# RP2040 register map
Vendor: Raspberry Pi; Series: RP; File version: 0.1
CPU: CM0PLUS r0p1, little endian, MPU, no FPU, VTOR, 2 interrupt priority bits, 32 interrupts
Registers are 32-bit, read-write, reset 0x0 unless marked. A register's access mark holds for its fields unless they carry their own. Offsets are from the block's base; [hi:lo] are bit positions; {n}, {i} and the like mark numbered series; 'fields as' and 'values as' point back to an identical list.

## CLOCKS
Base 0x40008000
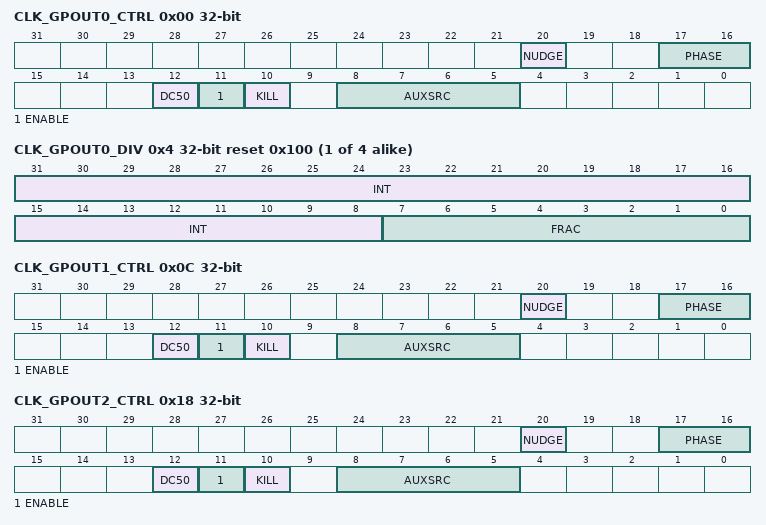
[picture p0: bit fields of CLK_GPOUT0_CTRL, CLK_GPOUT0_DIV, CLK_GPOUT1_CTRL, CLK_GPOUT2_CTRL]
0x00 CLK_GPOUT0_CTRL — Clock control, can be changed on-the-fly (except for auxsrc)
  [20] NUDGE — An edge on this signal shifts the phase of the output by 1 cycle of the input clock This can be done at any time
  [17:16] PHASE — This delays the enable signal by up to 3 cycles of the input clock This must be set before the clock is enabled to have any effect
  [12] DC50 — Enables duty cycle correction for odd divisors
  [11] ENABLE — Starts and stops the clock generator cleanly
  [10] KILL — Asynchronously kills the clock generator
  [8:5] AUXSRC — Selects the auxiliary clock source, will glitch when switching
    0=clksrc_pll_sys; 1=clksrc_gpin0; 2=clksrc_gpin1; 3=clksrc_pll_usb; 4=rosc_clksrc; 5=xosc_clksrc; 6=clk_sys; 7=clk_usb; 8=clk_adc; 9=clk_rtc; 10=clk_ref
{0x4+0xC*i} CLK_GPOUT{i}_DIV reset 0x100 (i=0..3) — Clock divisor, can be changed on-the-fly
  [31:8] INT — Integer component of the divisor, 0 -> divide by 2^16
  [7:0] FRAC — Fractional component of the divisor
{0x8+0xC*i} CLK_GPOUT{i}_SELECTED reset 0x1 (i=0..3) — Indicates which SRC is currently selected by the glitchless mux (one-hot).
  [31:0] CLK_GPOUT{i}_SELECTED ro — This slice does not have a glitchless mux (only the AUX_SRC field is present, not SRC) so this register is hardwired to 0x1.
0x0C CLK_GPOUT1_CTRL — Clock control, can be changed on-the-fly (except for auxsrc)
  fields as CLK_GPOUT0_CTRL
0x18 CLK_GPOUT2_CTRL — Clock control, can be changed on-the-fly (except for auxsrc)
  [20] NUDGE — An edge on this signal shifts the phase of the output by 1 cycle of the input clock This can be done at any time
  [17:16] PHASE — This delays the enable signal by up to 3 cycles of the input clock This must be set before the clock is enabled to have any effect
  [12] DC50 — Enables duty cycle correction for odd divisors
  [11] ENABLE — Starts and stops the clock generator cleanly
  [10] KILL — Asynchronously kills the clock generator
  [8:5] AUXSRC — Selects the auxiliary clock source, will glitch when switching
    0=clksrc_pll_sys; 1=clksrc_gpin0; 2=clksrc_gpin1; 3=clksrc_pll_usb; 4=rosc_clksrc_ph; 5=xosc_clksrc; 6=clk_sys; 7=clk_usb; 8=clk_adc; 9=clk_rtc; 10=clk_ref
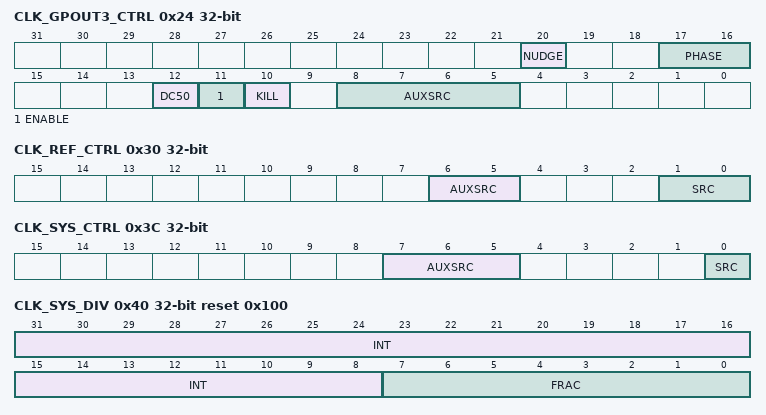
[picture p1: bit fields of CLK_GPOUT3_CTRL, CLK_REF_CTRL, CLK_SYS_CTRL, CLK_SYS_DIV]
0x24 CLK_GPOUT3_CTRL — Clock control, can be changed on-the-fly (except for auxsrc)
  fields as CLK_GPOUT2_CTRL
0x30 CLK_REF_CTRL — Clock control, can be changed on-the-fly (except for auxsrc)
  [6:5] AUXSRC — Selects the auxiliary clock source, will glitch when switching
    0=clksrc_pll_usb; 1=clksrc_gpin0; 2=clksrc_gpin1
  [1:0] SRC — Selects the clock source glitchlessly, can be changed on-the-fly
    0=rosc_clksrc_ph; 1=clksrc_clk_ref_aux; 2=xosc_clksrc
0x34 CLK_REF_DIV reset 0x100 — Clock divisor, can be changed on-the-fly
  [9:8] INT — Integer component of the divisor, 0 -> divide by 2^16
0x38 CLK_REF_SELECTED reset 0x1 — Indicates which SRC is currently selected by the glitchless mux (one-hot).
  [31:0] CLK_REF_SELECTED ro — The glitchless multiplexer does not switch instantaneously (to avoid glitches), so software should poll this register to wait for the switch to complete. This register contains one decoded bit for each of the clock sources enumerated in the CTRL SRC field. At most one of these bits will be set at any time, indicating that clock is currently present at the output of the glitchless mux. Whilst switching is in progress, this register may briefly show all-0s.
0x3C CLK_SYS_CTRL — Clock control, can be changed on-the-fly (except for auxsrc)
  [7:5] AUXSRC — Selects the auxiliary clock source, will glitch when switching
    0=clksrc_pll_sys; 1=clksrc_pll_usb; 2=rosc_clksrc; 3=xosc_clksrc; 4=clksrc_gpin0; 5=clksrc_gpin1
  [0] SRC — Selects the clock source glitchlessly, can be changed on-the-fly
    0=clk_ref; 1=clksrc_clk_sys_aux
0x40 CLK_SYS_DIV reset 0x100 — Clock divisor, can be changed on-the-fly
  fields as CLK_GPOUT0_DIV
0x44 CLK_SYS_SELECTED reset 0x1 — Indicates which SRC is currently selected by the glitchless mux (one-hot).
  [31:0] CLK_SYS_SELECTED ro — The glitchless multiplexer does not switch instantaneously (to avoid glitches), so software should poll this register to wait for the switch to complete. This register contains one decoded bit for each of the clock sources enumerated in the CTRL SRC field. At most one of these bits will be set at any time, indicating that clock is currently present at the output of the glitchless mux. Whilst switching is in progress, this register may briefly show all-0s.
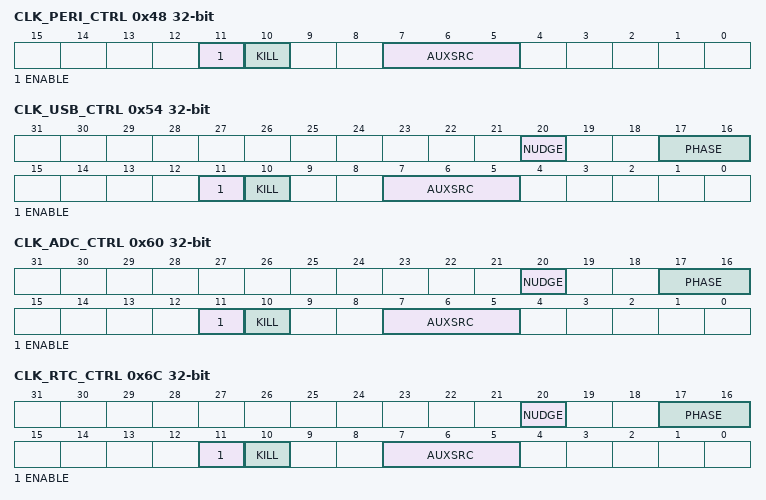
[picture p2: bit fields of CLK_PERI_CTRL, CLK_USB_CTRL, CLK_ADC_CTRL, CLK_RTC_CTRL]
0x48 CLK_PERI_CTRL — Clock control, can be changed on-the-fly (except for auxsrc)
  [11] ENABLE — Starts and stops the clock generator cleanly
  [10] KILL — Asynchronously kills the clock generator
  [7:5] AUXSRC — Selects the auxiliary clock source, will glitch when switching
    0=clk_sys; 1=clksrc_pll_sys; 2=clksrc_pll_usb; 3=rosc_clksrc_ph; 4=xosc_clksrc; 5=clksrc_gpin0; 6=clksrc_gpin1
0x50 CLK_PERI_SELECTED reset 0x1 — Indicates which SRC is currently selected by the glitchless mux (one-hot).
  [31:0] CLK_PERI_SELECTED ro — This slice does not have a glitchless mux (only the AUX_SRC field is present, not SRC) so this register is hardwired to 0x1.
0x54 CLK_USB_CTRL — Clock control, can be changed on-the-fly (except for auxsrc)
  [20] NUDGE — An edge on this signal shifts the phase of the output by 1 cycle of the input clock This can be done at any time
  [17:16] PHASE — This delays the enable signal by up to 3 cycles of the input clock This must be set before the clock is enabled to have any effect
  [11] ENABLE — Starts and stops the clock generator cleanly
  [10] KILL — Asynchronously kills the clock generator
  [7:5] AUXSRC — Selects the auxiliary clock source, will glitch when switching
    0=clksrc_pll_usb; 1=clksrc_pll_sys; 2=rosc_clksrc_ph; 3=xosc_clksrc; 4=clksrc_gpin0; 5=clksrc_gpin1
0x58 CLK_USB_DIV reset 0x100 — Clock divisor, can be changed on-the-fly
  [9:8] INT — Integer component of the divisor, 0 -> divide by 2^16
0x5C CLK_USB_SELECTED reset 0x1 — Indicates which SRC is currently selected by the glitchless mux (one-hot).
  [31:0] CLK_USB_SELECTED ro — This slice does not have a glitchless mux (only the AUX_SRC field is present, not SRC) so this register is hardwired to 0x1.
0x60 CLK_ADC_CTRL — Clock control, can be changed on-the-fly (except for auxsrc)
  fields as CLK_USB_CTRL
0x64 CLK_ADC_DIV reset 0x100 — Clock divisor, can be changed on-the-fly
  [9:8] INT — Integer component of the divisor, 0 -> divide by 2^16
0x68 CLK_ADC_SELECTED reset 0x1 — Indicates which SRC is currently selected by the glitchless mux (one-hot).
  [31:0] CLK_ADC_SELECTED ro — This slice does not have a glitchless mux (only the AUX_SRC field is present, not SRC) so this register is hardwired to 0x1.
0x6C CLK_RTC_CTRL — Clock control, can be changed on-the-fly (except for auxsrc)
  fields as CLK_USB_CTRL
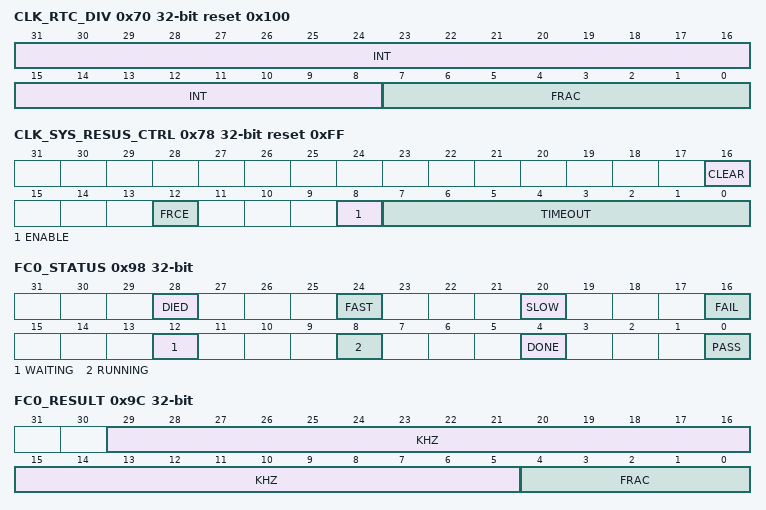
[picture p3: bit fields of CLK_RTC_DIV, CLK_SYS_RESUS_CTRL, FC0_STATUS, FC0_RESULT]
0x70 CLK_RTC_DIV reset 0x100 — Clock divisor, can be changed on-the-fly
  fields as CLK_GPOUT0_DIV
0x74 CLK_RTC_SELECTED reset 0x1 — Indicates which SRC is currently selected by the glitchless mux (one-hot).
  [31:0] CLK_RTC_SELECTED ro — This slice does not have a glitchless mux (only the AUX_SRC field is present, not SRC) so this register is hardwired to 0x1.
0x78 CLK_SYS_RESUS_CTRL reset 0xFF
  [16] CLEAR — For clearing the resus after the fault that triggered it has been corrected
  [12] FRCE — Force a resus, for test purposes only
  [8] ENABLE — Enable resus
  [7:0] TIMEOUT — This is expressed as a number of clk_ref cycles and must be >= 2x clk_ref_freq/min_clk_tst_freq
0x7C CLK_SYS_RESUS_STATUS
  [0] RESUSSED ro — Clock has been resuscitated, correct the error then send ctrl_clear=1
0x80 FC0_REF_KHZ — Reference clock frequency in kHz
  [19:0] FC0_REF_KHZ
0x84 FC0_MIN_KHZ — Minimum pass frequency in kHz. This is optional. Set to 0 if you are not using the pass/fail flags
  [24:0] FC0_MIN_KHZ
0x88 FC0_MAX_KHZ reset 0x1FFFFFF — Maximum pass frequency in kHz. This is optional. Set to 0x1ffffff if you are not using the pass/fail flags
  [24:0] FC0_MAX_KHZ
0x8C FC0_DELAY reset 0x1 — Delays the start of frequency counting to allow the mux to settle Delay is measured in multiples of the reference clock period
  [2:0] FC0_DELAY
0x90 FC0_INTERVAL reset 0x8 — The test interval is 0.98us * 2**interval, but let's call it 1us * 2**interval The default gives a test interval of 250us
  [3:0] FC0_INTERVAL
0x94 FC0_SRC — Clock sent to frequency counter, set to 0 when not required Writing to this register initiates the frequency count
  [7:0] FC0_SRC
    0=NULL; 1=pll_sys_clksrc_primary; 2=pll_usb_clksrc_primary; 3=rosc_clksrc; 4=rosc_clksrc_ph; 5=xosc_clksrc; 6=clksrc_gpin0; 7=clksrc_gpin1; 8=clk_ref; 9=clk_sys; 10=clk_peri; 11=clk_usb; 12=clk_adc; 13=clk_rtc
0x98 FC0_STATUS — Frequency counter status
  [28] DIED ro — Test clock stopped during test
  [24] FAST ro — Test clock faster than expected, only valid when status_done=1
  [20] SLOW ro — Test clock slower than expected, only valid when status_done=1
  [16] FAIL ro — Test failed
  [12] WAITING ro — Waiting for test clock to start
  [8] RUNNING ro — Test running
  [4] DONE ro — Test complete
  [0] PASS ro — Test passed
0x9C FC0_RESULT — Result of frequency measurement, only valid when status_done=1
  [29:5] KHZ ro, [4:0] FRAC ro
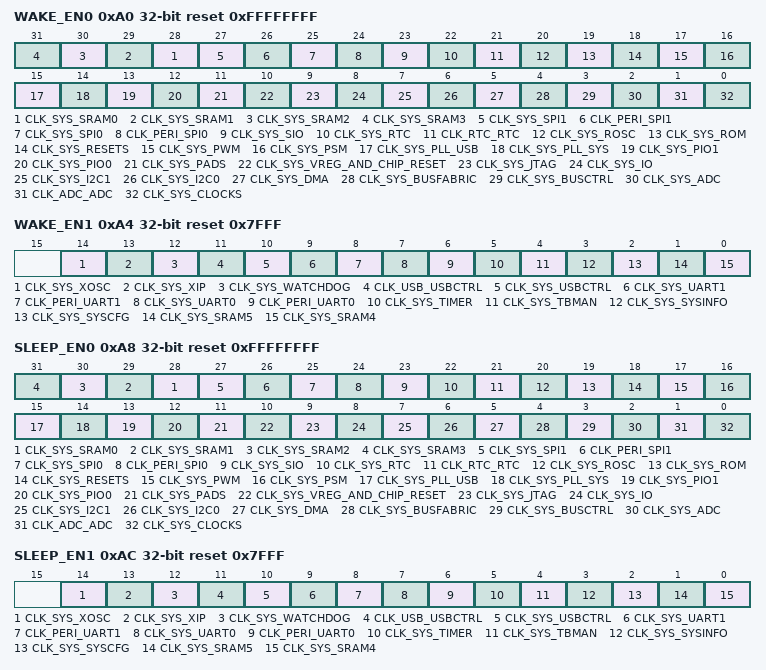
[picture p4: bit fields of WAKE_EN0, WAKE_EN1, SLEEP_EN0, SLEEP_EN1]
0xA0 WAKE_EN0 reset 0xFFFFFFFF — enable clock in wake mode
  [n+28] CLK_SYS_SRAM{n} (n=0..3), [27] CLK_SYS_SPI1, [26] CLK_PERI_SPI1, [25] CLK_SYS_SPI0, [24] CLK_PERI_SPI0, [23] CLK_SYS_SIO, [22] CLK_SYS_RTC, [21] CLK_RTC_RTC, [20] CLK_SYS_ROSC, [19] CLK_SYS_ROM, [18] CLK_SYS_RESETS, [17] CLK_SYS_PWM, [16] CLK_SYS_PSM, [15] CLK_SYS_PLL_USB, [14] CLK_SYS_PLL_SYS, [13] CLK_SYS_PIO1, [12] CLK_SYS_PIO0, [11] CLK_SYS_PADS, [10] CLK_SYS_VREG_AND_CHIP_RESET, [9] CLK_SYS_JTAG, [8] CLK_SYS_IO, [7] CLK_SYS_I2C1, [6] CLK_SYS_I2C0, [5] CLK_SYS_DMA, [4] CLK_SYS_BUSFABRIC, [3] CLK_SYS_BUSCTRL, [2] CLK_SYS_ADC, [1] CLK_ADC_ADC, [0] CLK_SYS_CLOCKS
0xA4 WAKE_EN1 reset 0x7FFF — enable clock in wake mode
  [14] CLK_SYS_XOSC, [13] CLK_SYS_XIP, [12] CLK_SYS_WATCHDOG, [11] CLK_USB_USBCTRL, [10] CLK_SYS_USBCTRL, [9] CLK_SYS_UART1, [8] CLK_PERI_UART1, [7] CLK_SYS_UART0, [6] CLK_PERI_UART0, [5] CLK_SYS_TIMER, [4] CLK_SYS_TBMAN, [3] CLK_SYS_SYSINFO, [2] CLK_SYS_SYSCFG, [1] CLK_SYS_SRAM5, [0] CLK_SYS_SRAM4
0xA8 SLEEP_EN0 reset 0xFFFFFFFF — enable clock in sleep mode
  fields as WAKE_EN0
0xAC SLEEP_EN1 reset 0x7FFF — enable clock in sleep mode
  fields as WAKE_EN1
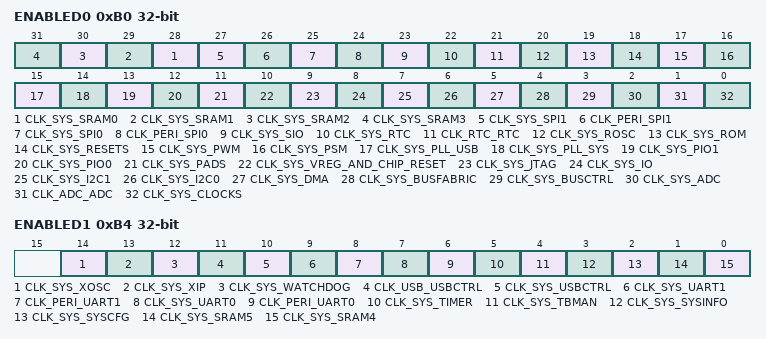
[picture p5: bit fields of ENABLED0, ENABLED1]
0xB0 ENABLED0 — indicates the state of the clock enable
  [n+28] CLK_SYS_SRAM{n} ro (n=0..3), [27] CLK_SYS_SPI1 ro, [26] CLK_PERI_SPI1 ro, [25] CLK_SYS_SPI0 ro, [24] CLK_PERI_SPI0 ro, [23] CLK_SYS_SIO ro, [22] CLK_SYS_RTC ro, [21] CLK_RTC_RTC ro, [20] CLK_SYS_ROSC ro, [19] CLK_SYS_ROM ro, [18] CLK_SYS_RESETS ro, [17] CLK_SYS_PWM ro, [16] CLK_SYS_PSM ro, [15] CLK_SYS_PLL_USB ro, [14] CLK_SYS_PLL_SYS ro, [13] CLK_SYS_PIO1 ro, [12] CLK_SYS_PIO0 ro, [11] CLK_SYS_PADS ro, [10] CLK_SYS_VREG_AND_CHIP_RESET ro, [9] CLK_SYS_JTAG ro, [8] CLK_SYS_IO ro, [7] CLK_SYS_I2C1 ro, [6] CLK_SYS_I2C0 ro, [5] CLK_SYS_DMA ro, [4] CLK_SYS_BUSFABRIC ro, [3] CLK_SYS_BUSCTRL ro, [2] CLK_SYS_ADC ro, [1] CLK_ADC_ADC ro, [0] CLK_SYS_CLOCKS ro
0xB4 ENABLED1 — indicates the state of the clock enable
  [14] CLK_SYS_XOSC ro, [13] CLK_SYS_XIP ro, [12] CLK_SYS_WATCHDOG ro, [11] CLK_USB_USBCTRL ro, [10] CLK_SYS_USBCTRL ro, [9] CLK_SYS_UART1 ro, [8] CLK_PERI_UART1 ro, [7] CLK_SYS_UART0 ro, [6] CLK_PERI_UART0 ro, [5] CLK_SYS_TIMER ro, [4] CLK_SYS_TBMAN ro, [3] CLK_SYS_SYSINFO ro, [2] CLK_SYS_SYSCFG ro, [1] CLK_SYS_SRAM5 ro, [0] CLK_SYS_SRAM4 ro
0xB8 INTR — Raw Interrupts
  [0] CLK_SYS_RESUS ro
0xBC INTE — Interrupt Enable
  [0] CLK_SYS_RESUS
0xC0 INTF — Interrupt Force
  [0] CLK_SYS_RESUS
0xC4 INTS — Interrupt status after masking & forcing
  [0] CLK_SYS_RESUS ro
